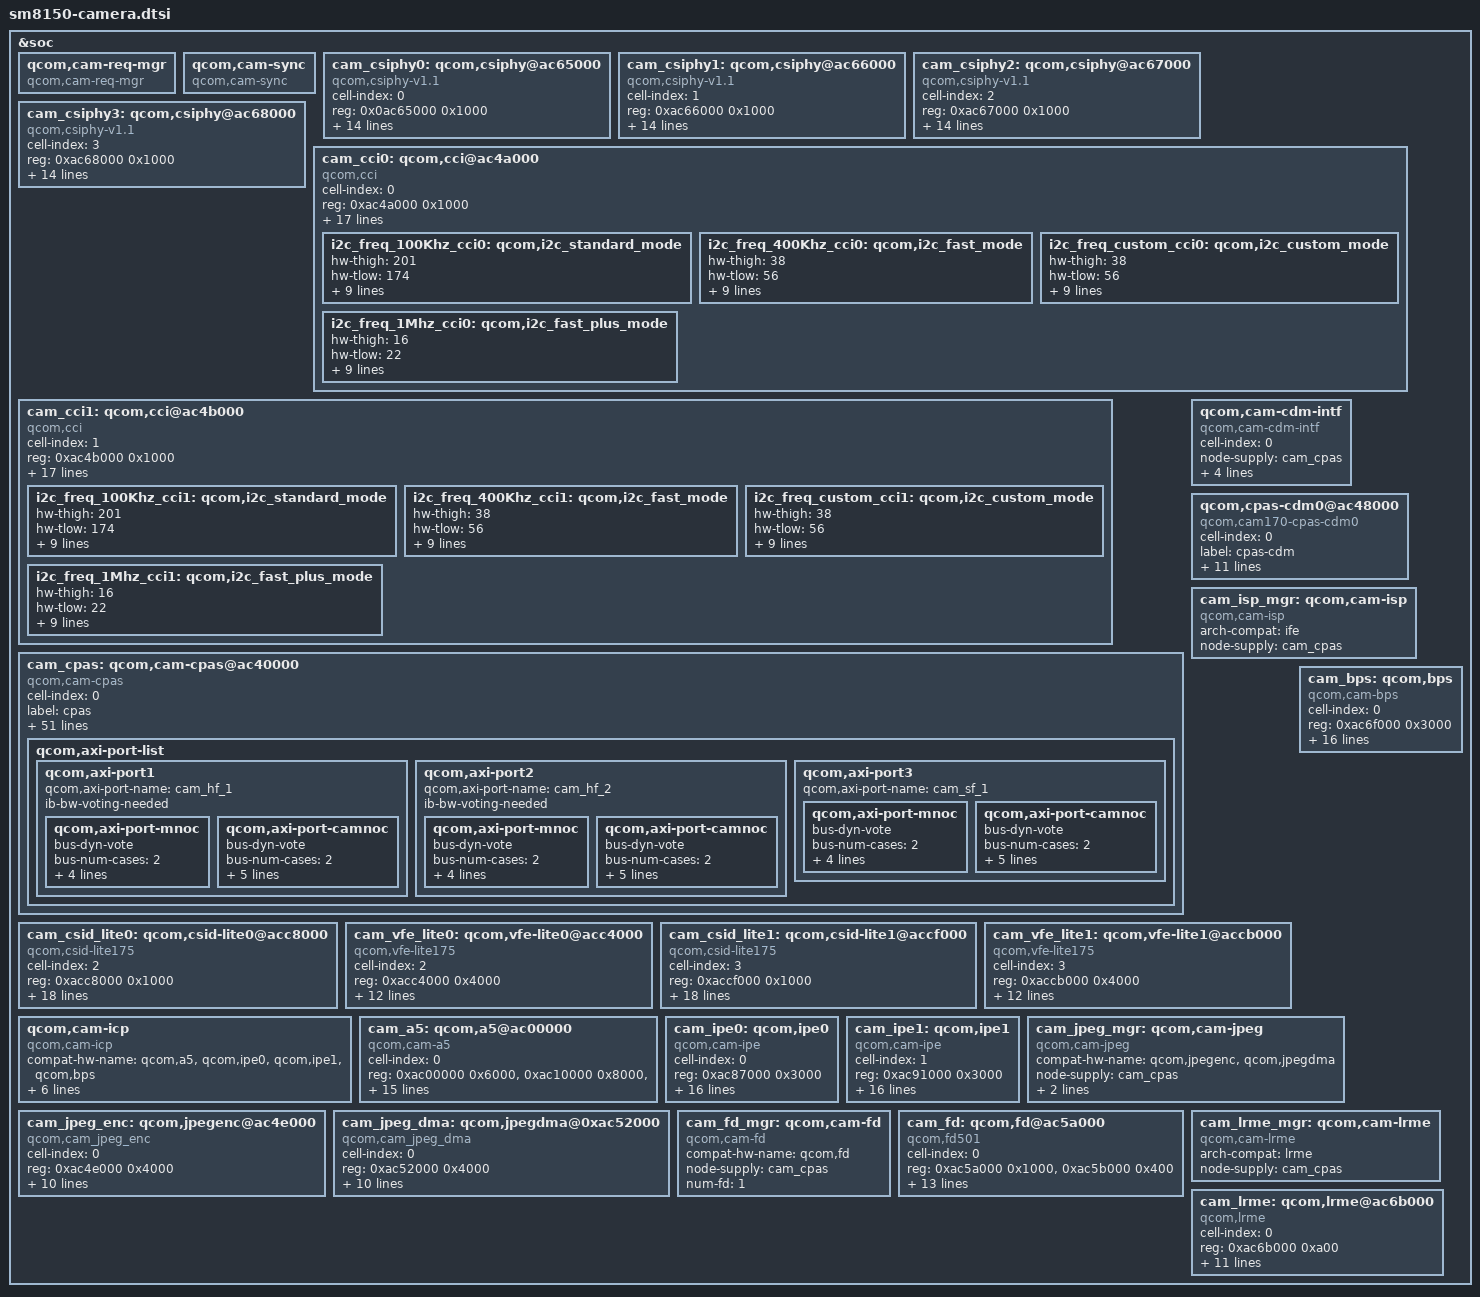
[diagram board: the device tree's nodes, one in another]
&soc {
	qcom,cam-req-mgr {
		compatible = "qcom,cam-req-mgr";
		status = "ok";
	};

	qcom,cam-sync {
		compatible = "qcom,cam-sync";
		status = "ok";
	};

	cam_csiphy0: qcom,csiphy@ac65000 {
		cell-index = <0>;
		compatible = "qcom,csiphy-v1.1", "qcom,csiphy";
		reg = <0x0ac65000 0x1000>;
		reg-names = "csiphy";
		reg-cam-base = <0x65000>;
		interrupts = <GIC_SPI 477 IRQ_TYPE_EDGE_RISING>;
		interrupt-names = "csiphy";
		gdscr-supply = <&titan_top_gdsc>;
		regulator-names = "gdscr";
		csi-vdd-voltage = <1200000>;
		mipi-csi-vdd-supply = <&pm8150l_l3>;
		clocks = <&camcc CAM_CC_CPHY_RX_CLK_SRC>,
			<&camcc CAM_CC_CSIPHY0_CLK>,
			<&camcc CAM_CC_CSI0PHYTIMER_CLK_SRC>,
			<&camcc CAM_CC_CSI0PHYTIMER_CLK>;
		clock-names = "cphy_rx_clk_src",
			"csiphy0_clk",
			"csi0phytimer_clk_src",
			"csi0phytimer_clk";
		src-clock-name = "csi0phytimer_clk_src";
		clock-cntl-level = "turbo";
		clock-rates =
			<400000000 0 300000000 0>;
		status = "ok";
		node-supply = <&cam_cpas>;
	};

	cam_csiphy1: qcom,csiphy@ac66000{
		cell-index = <1>;
		compatible = "qcom,csiphy-v1.1", "qcom,csiphy";
		reg = <0xac66000 0x1000>;
		reg-names = "csiphy";
		reg-cam-base = <0x66000>;
		interrupts = <GIC_SPI 478 IRQ_TYPE_EDGE_RISING>;
		interrupt-names = "csiphy";
		gdscr-supply = <&titan_top_gdsc>;
		regulator-names = "gdscr";
		csi-vdd-voltage = <1200000>;
		mipi-csi-vdd-supply = <&pm8150l_l3>;
		clocks = <&camcc CAM_CC_CPHY_RX_CLK_SRC>,
			<&camcc CAM_CC_CSIPHY1_CLK>,
			<&camcc CAM_CC_CSI1PHYTIMER_CLK_SRC>,
			<&camcc CAM_CC_CSI1PHYTIMER_CLK>;
		clock-names = "cphy_rx_clk_src",
			"csiphy1_clk",
			"csi1phytimer_clk_src",
			"csi1phytimer_clk";
		src-clock-name = "csi1phytimer_clk_src";
		clock-cntl-level = "turbo";
		clock-rates =
			<400000000 0 300000000 0>;

		status = "ok";
		node-supply = <&cam_cpas>;
	};

	cam_csiphy2: qcom,csiphy@ac67000 {
		cell-index = <2>;
		compatible = "qcom,csiphy-v1.1", "qcom,csiphy";
		reg = <0xac67000 0x1000>;
		reg-names = "csiphy";
		reg-cam-base = <0x67000>;
		interrupts = <GIC_SPI 479 IRQ_TYPE_EDGE_RISING>;
		interrupt-names = "csiphy";
		gdscr-supply = <&titan_top_gdsc>;
		regulator-names = "gdscr";
		csi-vdd-voltage = <1200000>;
		mipi-csi-vdd-supply = <&pm8150l_l3>;
		clocks = <&camcc CAM_CC_CPHY_RX_CLK_SRC>,
			<&camcc CAM_CC_CSIPHY2_CLK>,
			<&camcc CAM_CC_CSI2PHYTIMER_CLK_SRC>,
			<&camcc CAM_CC_CSI2PHYTIMER_CLK>;
		clock-names = "cphy_rx_clk_src",
			"csiphy2_clk",
			"csi2phytimer_clk_src",
			"csi2phytimer_clk";
		src-clock-name = "csi2phytimer_clk_src";
		clock-cntl-level = "turbo";
		clock-rates =
			<400000000 0 300000000 0>;
		status = "ok";
		node-supply = <&cam_cpas>;
	};

	cam_csiphy3: qcom,csiphy@ac68000 {
		cell-index = <3>;
		compatible = "qcom,csiphy-v1.1", "qcom,csiphy";
		reg = <0xac68000 0x1000>;
		reg-names = "csiphy";
		reg-cam-base = <0x68000>;
		interrupts = <GIC_SPI 448 IRQ_TYPE_EDGE_RISING>;
		interrupt-names = "csiphy";
		gdscr-supply = <&titan_top_gdsc>;
		regulator-names = "gdscr";
		csi-vdd-voltage = <1200000>;
		mipi-csi-vdd-supply = <&pm8150l_l3>;
		clocks = <&camcc CAM_CC_CPHY_RX_CLK_SRC>,
			<&camcc CAM_CC_CSIPHY3_CLK>,
			<&camcc CAM_CC_CSI3PHYTIMER_CLK_SRC>,
			<&camcc CAM_CC_CSI3PHYTIMER_CLK>;
		clock-names = "cphy_rx_clk_src",
			"csiphy3_clk",
			"csi3phytimer_clk_src",
			"csi3phytimer_clk";
		src-clock-name = "csi3phytimer_clk_src";
		clock-cntl-level = "turbo";
		clock-rates =
			<400000000 0 300000000 0>;
		status = "ok";
		node-supply = <&cam_cpas>;
	};

	cam_cci0: qcom,cci@ac4a000 {
		cell-index = <0>;
		compatible = "qcom,cci", "simple-bus";
		#address-cells = <1>;
		#size-cells = <0>;
		reg = <0xac4a000 0x1000>;
		reg-names = "cci";
		reg-cam-base = <0x4a000>;
		interrupt-names = "cci";
		interrupts = <GIC_SPI 460 IRQ_TYPE_EDGE_RISING>;
		status = "ok";
		gdscr-supply = <&titan_top_gdsc>;
		regulator-names = "gdscr";
		clocks = <&camcc CAM_CC_CCI_0_CLK_SRC>,
			<&camcc CAM_CC_CCI_0_CLK>;
		clock-names = "cci_0_clk_src",
			"cci_0_clk";
		src-clock-name = "cci_0_clk_src";
		clock-cntl-level = "lowsvs";
		clock-rates = <37500000 0>;
		pinctrl-names = "cam_default", "cam_suspend";
		pinctrl-0 = <&cci0_active &cci1_active>;
		pinctrl-1 = <&cci0_suspend &cci1_suspend>;
		node-supply = <&cam_cpas>;
		gpios = <&tlmm 17 0>,
			<&tlmm 18 0>,
			<&tlmm 19 0>,
			<&tlmm 20 0>;
		gpio-req-tbl-num = <0 1 2 3>;
		gpio-req-tbl-flags = <1 1 1 1>;
		gpio-req-tbl-label = "CCI_I2C_DATA0",
					"CCI_I2C_CLK0",
					"CCI_I2C_DATA1",
					"CCI_I2C_CLK1";

		i2c_freq_100Khz_cci0: qcom,i2c_standard_mode {
			hw-thigh = <201>;
			hw-tlow = <174>;
			hw-tsu-sto = <204>;
			hw-tsu-sta = <231>;
			hw-thd-dat = <22>;
			hw-thd-sta = <162>;
			hw-tbuf = <227>;
			hw-scl-stretch-en = <0>;
			hw-trdhld = <6>;
			hw-tsp = <3>;
			cci-clk-src = <37500000>;
			status = "ok";
		};

		i2c_freq_400Khz_cci0: qcom,i2c_fast_mode {
			hw-thigh = <38>;
			hw-tlow = <56>;
			hw-tsu-sto = <40>;
			hw-tsu-sta = <40>;
			hw-thd-dat = <22>;
			hw-thd-sta = <35>;
			hw-tbuf = <62>;
			hw-scl-stretch-en = <0>;
			hw-trdhld = <6>;
			hw-tsp = <3>;
			cci-clk-src = <37500000>;
			status = "ok";
		};

		i2c_freq_custom_cci0: qcom,i2c_custom_mode {
			hw-thigh = <38>;
			hw-tlow = <56>;
			hw-tsu-sto = <40>;
			hw-tsu-sta = <40>;
			hw-thd-dat = <22>;
			hw-thd-sta = <35>;
			hw-tbuf = <62>;
			hw-scl-stretch-en = <1>;
			hw-trdhld = <6>;
			hw-tsp = <3>;
			cci-clk-src = <37500000>;
			status = "ok";
		};

		i2c_freq_1Mhz_cci0: qcom,i2c_fast_plus_mode {
			hw-thigh = <16>;
			hw-tlow = <22>;
			hw-tsu-sto = <17>;
			hw-tsu-sta = <18>;
			hw-thd-dat = <16>;
			hw-thd-sta = <15>;
			hw-tbuf = <24>;
			hw-scl-stretch-en = <0>;
			hw-trdhld = <3>;
			hw-tsp = <3>;
			cci-clk-src = <37500000>;
			status = "ok";
		};
	};

	cam_cci1: qcom,cci@ac4b000 {
		cell-index = <1>;
		compatible = "qcom,cci", "simple-bus";
		#address-cells = <1>;
		#size-cells = <0>;
		reg = <0xac4b000 0x1000>;
		reg-names = "cci";
		reg-cam-base = <0x4b000>;
		interrupt-names = "cci";
		interrupts = <GIC_SPI 271 IRQ_TYPE_EDGE_RISING>;
		status = "ok";
		gdscr-supply = <&titan_top_gdsc>;
		regulator-names = "gdscr";
		clocks = <&camcc CAM_CC_CCI_1_CLK_SRC>,
			<&camcc CAM_CC_CCI_1_CLK>;
		clock-names = "cci_1_clk_src",
			"cci_1_clk";
		src-clock-name = "cci_1_clk_src";
		clock-cntl-level = "lowsvs";
		clock-rates = <37500000 0>;
		pinctrl-names = "cam_default", "cam_suspend";
		pinctrl-0 = <&cci2_active &cci3_active>;
		pinctrl-1 = <&cci2_suspend &cci3_suspend>;
		node-supply = <&cam_cpas>;
		gpios = <&tlmm 31 0>,
			<&tlmm 32 0>,
			<&tlmm 33 0>,
			<&tlmm 34 0>;
		gpio-req-tbl-num = <0 1 2 3>;
		gpio-req-tbl-flags = <1 1 1 1>;
		gpio-req-tbl-label = "CCI_I2C_DATA2",
					"CCI_I2C_CLK2",
					"CCI_I2C_DATA3",
					"CCI_I2C_CLK3";

		i2c_freq_100Khz_cci1: qcom,i2c_standard_mode {
			hw-thigh = <201>;
			hw-tlow = <174>;
			hw-tsu-sto = <204>;
			hw-tsu-sta = <231>;
			hw-thd-dat = <22>;
			hw-thd-sta = <162>;
			hw-tbuf = <227>;
			hw-scl-stretch-en = <0>;
			hw-trdhld = <6>;
			hw-tsp = <3>;
			cci-clk-src = <37500000>;
			status = "ok";
		};

		i2c_freq_400Khz_cci1: qcom,i2c_fast_mode {
			hw-thigh = <38>;
			hw-tlow = <56>;
			hw-tsu-sto = <40>;
			hw-tsu-sta = <40>;
			hw-thd-dat = <22>;
			hw-thd-sta = <35>;
			hw-tbuf = <62>;
			hw-scl-stretch-en = <0>;
			hw-trdhld = <6>;
			hw-tsp = <3>;
			cci-clk-src = <37500000>;
			status = "ok";
		};

		i2c_freq_custom_cci1: qcom,i2c_custom_mode {
			hw-thigh = <38>;
			hw-tlow = <56>;
			hw-tsu-sto = <40>;
			hw-tsu-sta = <40>;
			hw-thd-dat = <22>;
			hw-thd-sta = <35>;
			hw-tbuf = <62>;
			hw-scl-stretch-en = <1>;
			hw-trdhld = <6>;
			hw-tsp = <3>;
			cci-clk-src = <37500000>;
			status = "ok";
		};

		i2c_freq_1Mhz_cci1: qcom,i2c_fast_plus_mode {
			hw-thigh = <16>;
			hw-tlow = <22>;
			hw-tsu-sto = <17>;
			hw-tsu-sta = <18>;
			hw-thd-dat = <16>;
			hw-thd-sta = <15>;
			hw-tbuf = <24>;
			hw-scl-stretch-en = <0>;
			hw-trdhld = <3>;
			hw-tsp = <3>;
			cci-clk-src = <37500000>;
			status = "ok";
		};
	};

	cam_cpas: qcom,cam-cpas@ac40000 {
		cell-index = <0>;
		compatible = "qcom,cam-cpas";
		label = "cpas";
		arch-compat = "cpas_top";
		status = "ok";
		reg-names = "cam_cpas_top", "cam_camnoc";
		reg = <0xac40000 0x1000>,
			<0xac42000 0x5000>;
		reg-cam-base = <0x40000 0x42000>;
		interrupt-names = "cpas_camnoc";
		interrupts = <GIC_SPI 459 IRQ_TYPE_EDGE_RISING>;
		camnoc-axi-min-ib-bw = <3000000000>;
		regulator-names = "camss-vdd";
		camss-vdd-supply = <&titan_top_gdsc>;
		clock-names =
			"gcc_axi_hf_clk",
			"gcc_axi_sf_clk",
			"slow_ahb_clk_src",
			"cpas_ahb_clk",
			"camnoc_axi_clk_src",
			"camnoc_axi_clk";
		clocks =
			<&gcc GCC_CAMERA_HF_AXI_CLK>,
			<&gcc GCC_CAMERA_SF_AXI_CLK>,
			<&camcc CAM_CC_SLOW_AHB_CLK_SRC>,
			<&camcc CAM_CC_CPAS_AHB_CLK>,
			<&camcc CAM_CC_CAMNOC_AXI_CLK_SRC>,
			<&camcc CAM_CC_CAMNOC_AXI_CLK>;
		src-clock-name = "camnoc_axi_clk_src";
		clock-rates =
			<0 0 0 0 0 0>,
			<0 0 19200000 0 19200000 0>,
			<0 0 80000000 0 150000000 0>,
			<0 0 80000000 0 266670000 0>,
			<0 0 80000000 0 320000000 0>,
			<0 0 80000000 0 400000000 0>,
			<0 0 80000000 0 480000000 0>;
		clock-cntl-level = "suspend", "minsvs", "lowsvs", "svs",
			"svs_l1", "nominal", "turbo";
		control-camnoc-axi-clk;
		camnoc-bus-width = <32>;
		camnoc-axi-clk-bw-margin-perc = <20>;
		interconnect-names = "cam_ahb";
		interconnects =<&gem_noc MASTER_APPSS_PROC
			&config_noc SLAVE_CAMERA_CFG>;
		bus-num-cases = <7>;
		bus-num-paths = <1>;
		bus-bw-KBps =
			<0 0>, <0 76800>, <0 76800>, <0 150000>, <0 150000>,
			<0 300000>, <0 300000>;
		vdd-corners = <RPMH_REGULATOR_LEVEL_RETENTION
			RPMH_REGULATOR_LEVEL_MIN_SVS
			RPMH_REGULATOR_LEVEL_LOW_SVS
			RPMH_REGULATOR_LEVEL_SVS
			RPMH_REGULATOR_LEVEL_SVS_L1
			RPMH_REGULATOR_LEVEL_NOM
			RPMH_REGULATOR_LEVEL_NOM_L1
			RPMH_REGULATOR_LEVEL_NOM_L2
			RPMH_REGULATOR_LEVEL_TURBO
			RPMH_REGULATOR_LEVEL_TURBO_L1>;
		vdd-corner-ahb-mapping = "suspend",
			"minsvs", "lowsvs", "svs", "svs_l1",
			"nominal", "nominal", "nominal",
			"turbo", "turbo";
		client-id-based;
		client-names =
			"csiphy0", "csiphy1", "csiphy2", "csiphy3",
			"cci0", "cci1",
			"csid0", "csid1", "csid2", "csid3",
			"ife0", "ife1", "ife2", "ife3",
			"ipe0", "ipe1", "cam-cdm-intf0", "cpas-cdm0",
			"bps0", "icp0", "jpeg-dma0", "jpeg-enc0",
			"fd0", "lrmecpas0";
		client-axi-port-names =
			"cam_hf_1", "cam_hf_2", "cam_hf_1", "cam_hf_2",
			"cam_sf_1", "cam_sf_1",
			"cam_hf_1", "cam_hf_2", "cam_hf_1", "cam_hf_2",
			"cam_hf_1", "cam_hf_2", "cam_hf_1", "cam_hf_2",
			"cam_sf_1", "cam_sf_1", "cam_sf_1", "cam_sf_1",
			"cam_sf_1", "cam_sf_1", "cam_sf_1", "cam_sf_1",
			"cam_sf_1", "cam_sf_1";
		client-bus-camnoc-based;
		qcom,axi-port-list {
			qcom,axi-port1 {
				qcom,axi-port-name = "cam_hf_1";
				ib-bw-voting-needed;
				qcom,axi-port-mnoc {
					interconnect-names = "cam_hf_1_mnoc";
					bus-dyn-vote;
					bus-num-cases = <2>;
					bus-num-paths = <1>;
					interconnects = <&mmss_noc MASTER_CAMNOC_HF0
						&mc_virt SLAVE_EBI1>;
					bus-bw-KBps =
						<0 0>, <0 0>;
				};
				qcom,axi-port-camnoc {
					interconnect-names = "cam_hf_1_camnoc";
					bus-dyn-vote;
					bus-num-cases = <2>;
					bus-num-paths = <1>;
					interconnects = <&camnoc_virt MASTER_CAMNOC_HF0_UNCOMP
						&camnoc_virt SLAVE_CAMNOC_UNCOMP>;
					bus-bw-KBps =
						<0 0>, <0 0>;
				};
			};
			qcom,axi-port2 {
				qcom,axi-port-name = "cam_hf_2";
				ib-bw-voting-needed;
				qcom,axi-port-mnoc {
					interconnect-names = "cam_hf_2_mnoc";
					bus-dyn-vote;
					bus-num-cases = <2>;
					bus-num-paths = <1>;
					interconnects = <&mmss_noc MASTER_CAMNOC_HF1
						&mc_virt SLAVE_EBI1>;
					bus-bw-KBps =
						<0 0>, <0 0>;
				};
				qcom,axi-port-camnoc {
					interconnect-names = "cam_hf_2_camnoc";
					bus-dyn-vote;
					bus-num-cases = <2>;
					bus-num-paths = <1>;
					interconnects = <&camnoc_virt MASTER_CAMNOC_HF1_UNCOMP
						&camnoc_virt SLAVE_CAMNOC_UNCOMP>;
					bus-bw-KBps =
						<0 0>, <0 0>;
				};
			};
			qcom,axi-port3 {
				qcom,axi-port-name = "cam_sf_1";
				qcom,axi-port-mnoc {
					interconnect-names = "cam_sf_1_mnoc";
					bus-dyn-vote;
					bus-num-cases = <2>;
					bus-num-paths = <1>;
					interconnects = <&mmss_noc MASTER_CAMNOC_SF
						&mc_virt SLAVE_EBI1>;
					bus-bw-KBps =
						<0 0>, <0 0>;
				};
				qcom,axi-port-camnoc {
					interconnect-names = "cam_sf_1_camnoc";
					bus-dyn-vote;
					bus-num-cases = <2>;
					bus-num-paths = <1>;
					interconnects = <&camnoc_virt MASTER_CAMNOC_SF_UNCOMP
						&camnoc_virt SLAVE_CAMNOC_UNCOMP>;
					bus-bw-KBps =
						<0 0>, <0 0>;
				};
			};
		};
	};

	qcom,cam-cdm-intf {
		compatible = "qcom,cam-cdm-intf";
		cell-index = <0>;
		node-supply = <&cam_cpas>;
		label = "cam-cdm-intf";
		num-hw-cdm = <1>;
		cdm-client-names = "vfe",
			"jpegdma",
			"jpegenc",
			"fd",
			"lrmecdm";
		status = "ok";
	};

	qcom,cpas-cdm0@ac48000 {
		cell-index = <0>;
		compatible = "qcom,cam170-cpas-cdm0";
		label = "cpas-cdm";
		reg = <0xac48000 0x1000>;
		reg-names = "cpas-cdm";
		reg-cam-base = <0x48000>;
		interrupts = <GIC_SPI 461 IRQ_TYPE_EDGE_RISING>;
		interrupt-names = "cpas-cdm";
		regulator-names = "camss";
		camss-supply = <&titan_top_gdsc>;
		node-supply = <&cam_cpas>;
		clock-names = "cam_cc_cpas_slow_ahb_clk",
			"cam_cc_cpas_ahb_clk";
		clocks = <&camcc CAM_CC_SLOW_AHB_CLK_SRC>,
			<&camcc CAM_CC_CPAS_AHB_CLK>;
		clock-rates = <0 0>;
		clock-cntl-level = "svs";
		cdm-client-names = "ife";
		status = "ok";
	};

	cam_isp_mgr: qcom,cam-isp {
		compatible = "qcom,cam-isp";
		arch-compat = "ife";
		status = "ok";
		node-supply = <&cam_cpas>;
	};

	cam_csid_lite0: qcom,csid-lite0@acc8000 {
		cell-index = <2>;
		compatible = "qcom,csid-lite175";
		reg-names = "csid-lite";
		reg = <0xacc8000 0x1000>;
		reg-cam-base = <0xc8000>;
		interrupt-names = "csid-lite";
		interrupts = <GIC_SPI 468 IRQ_TYPE_EDGE_RISING>;
		regulator-names = "camss";
		camss-supply = <&titan_top_gdsc>;
		clock-names =
			"ife_csid_clk_src",
			"ife_csid_clk",
			"cphy_rx_clk_src",
			"ife_cphy_rx_clk",
			"ife_clk_src",
			"ife_clk";
		clocks =
			<&camcc CAM_CC_IFE_LITE_0_CSID_CLK_SRC>,
			<&camcc CAM_CC_IFE_LITE_0_CSID_CLK>,
			<&camcc CAM_CC_CPHY_RX_CLK_SRC>,
			<&camcc CAM_CC_IFE_LITE_0_CPHY_RX_CLK>,
			<&camcc CAM_CC_IFE_LITE_0_CLK_SRC>,
			<&camcc CAM_CC_IFE_LITE_0_CLK>;
		clock-rates =
			<400000000 0 0 0 320000000 0>,
			<400000000 0 0 0 400000000 0>,
			<480000000 0 0 0 480000000 0>,
			<600000000 0 0 0 600000000 0>;
		clock-cntl-level = "lowsvs", "svs", "svs_l1", "turbo";
		src-clock-name = "ife_csid_clk_src";
		clock-control-debugfs = "true";
		status = "ok";
		node-supply = <&cam_cpas>;
	};

	cam_vfe_lite0: qcom,vfe-lite0@acc4000 {
		cell-index = <2>;
		compatible = "qcom,vfe-lite175";
		reg-names = "ife-lite";
		reg = <0xacc4000 0x4000>;
		reg-cam-base = <0xc4000>;
		interrupt-names = "ife-lite";
		interrupts = <GIC_SPI 469 IRQ_TYPE_EDGE_RISING>;
		regulator-names = "camss";
		camss-supply = <&titan_top_gdsc>;
		clock-names =
			"ife_clk_src",
			"ife_clk";
		clocks =
			<&camcc CAM_CC_IFE_LITE_0_CLK_SRC>,
			<&camcc CAM_CC_IFE_LITE_0_CLK>;
		clock-rates =
			<320000000 0>,
			<400000000 0>,
			<480000000 0>,
			<600000000 0>;
		clock-cntl-level = "lowsvs", "svs", "svs_l1", "turbo";
		src-clock-name = "ife_clk_src";
		clock-control-debugfs = "true";
		status = "ok";
		node-supply = <&cam_cpas>;
	};

	cam_csid_lite1: qcom,csid-lite1@accf000 {
		cell-index = <3>;
		compatible = "qcom,csid-lite175";
		reg-names = "csid-lite";
		reg = <0xaccf000 0x1000>;
		reg-cam-base = <0xcf000>;
		interrupt-names = "csid-lite";
		interrupts = <GIC_SPI 359 IRQ_TYPE_EDGE_RISING>;
		regulator-names = "camss";
		camss-supply = <&titan_top_gdsc>;
		clock-names =
			"ife_csid_clk_src",
			"ife_csid_clk",
			"cphy_rx_clk_src",
			"ife_cphy_rx_clk",
			"ife_clk_src",
			"ife_clk";
		clocks =
			<&camcc CAM_CC_IFE_LITE_1_CSID_CLK_SRC>,
			<&camcc CAM_CC_IFE_LITE_1_CSID_CLK>,
			<&camcc CAM_CC_CPHY_RX_CLK_SRC>,
			<&camcc CAM_CC_IFE_LITE_1_CPHY_RX_CLK>,
			<&camcc CAM_CC_IFE_LITE_1_CLK_SRC>,
			<&camcc CAM_CC_IFE_LITE_1_CLK>;
		clock-rates =
			<400000000 0 0 0 320000000 0>,
			<400000000 0 0 0 400000000 0>,
			<480000000 0 0 0 480000000 0>,
			<600000000 0 0 0 600000000 0>;
		clock-cntl-level = "lowsvs", "svs", "svs_l1", "turbo";
		src-clock-name = "ife_csid_clk_src";
		clock-control-debugfs = "true";
		status = "ok";
		node-supply = <&cam_cpas>;
	};

	cam_vfe_lite1: qcom,vfe-lite1@accb000 {
		cell-index = <3>;
		compatible = "qcom,vfe-lite175";
		reg-names = "ife-lite";
		reg = <0xaccb000 0x4000>;
		reg-cam-base = <0xcb000>;
		interrupt-names = "ife-lite";
		interrupts = <GIC_SPI 360 IRQ_TYPE_EDGE_RISING>;
		regulator-names = "camss";
		camss-supply = <&titan_top_gdsc>;
		clock-names =
			"ife_clk_src",
			"ife_clk";
		clocks =
			<&camcc CAM_CC_IFE_LITE_1_CLK_SRC>,
			<&camcc CAM_CC_IFE_LITE_1_CLK>;
		clock-rates =
			<320000000 0>,
			<400000000 0>,
			<480000000 0>,
			<600000000 0>;
		clock-cntl-level = "lowsvs", "svs", "svs_l1", "turbo";
		src-clock-name = "ife_clk_src";
		clock-control-debugfs = "true";
		status = "ok";
		node-supply = <&cam_cpas>;
	};

	qcom,cam-icp {
		compatible = "qcom,cam-icp";
		compat-hw-name = "qcom,a5",
			"qcom,ipe0",
			"qcom,ipe1",
			"qcom,bps";
		num-a5 = <1>;
		num-ipe = <2>;
		num-bps = <1>;
		icp_pc_en;
		ipe_bps_pc_en;
		status = "ok";
		node-supply = <&cam_cpas>;
	};

	cam_a5: qcom,a5@ac00000 {
		cell-index = <0>;
		compatible = "qcom,cam-a5";
		reg = <0xac00000 0x6000>,
			<0xac10000 0x8000>,
			<0xac18000 0x3000>;
		reg-names = "a5_qgic", "a5_sierra", "a5_csr";
		reg-cam-base = <0x00000 0x10000 0x18000>;
		interrupts = <GIC_SPI 463 IRQ_TYPE_EDGE_RISING>;
		interrupt-names = "a5";
		regulator-names = "camss-vdd";
		camss-vdd-supply = <&titan_top_gdsc>;
		clock-names =
			"soc_fast_ahb",
			"icp_ahb_clk",
			"icp_clk_src",
			"icp_clk";
		clocks =
			<&camcc CAM_CC_FAST_AHB_CLK_SRC>,
			<&camcc CAM_CC_ICP_AHB_CLK>,
			<&camcc CAM_CC_ICP_CLK_SRC>,
			<&camcc CAM_CC_ICP_CLK>;
		clock-rates =
			<200000000 0 400000000 0>,
			<400000000 0 600000000 0>;
		clock-cntl-level = "svs", "turbo";
		fw_name = "CAMERA_ICP.elf";
		ubwc-cfg = <0x7B 0x1EF>;
		status = "ok";
		node-supply = <&cam_cpas>;
	};

	cam_ipe0: qcom,ipe0 {
		cell-index = <0>;
		compatible = "qcom,cam-ipe";
		reg = <0xac87000 0x3000>;
		reg-names = "ipe0_top";
		reg-cam-base = <0x87000>;
		regulator-names = "ipe0-vdd";
		ipe0-vdd-supply = <&ipe_0_gdsc>;
		clock-names =
			"ipe_0_ahb_clk",
			"ipe_0_areg_clk",
			"ipe_0_axi_clk",
			"ipe_0_clk_src",
			"ipe_0_clk";
		src-clock-name = "ipe_0_clk_src";
		clock-control-debugfs = "true";
		clocks =
			<&camcc CAM_CC_IPE_0_AHB_CLK>,
			<&camcc CAM_CC_IPE_0_AREG_CLK>,
			<&camcc CAM_CC_IPE_0_AXI_CLK>,
			<&camcc CAM_CC_IPE_0_CLK_SRC>,
			<&camcc CAM_CC_IPE_0_CLK>;
		clock-rates =
			<0 0 0 300000000 0>,
			<0 0 0 475000000 0>,
			<0 0 0 520000000 0>,
			<0 0 0 600000000 0>,
			<0 0 0 600000000 0>;
		clock-cntl-level = "lowsvs", "svs", "svs_l1",
				"nominal", "turbo";
		status = "ok";
		node-supply = <&cam_cpas>;
	};

	cam_ipe1: qcom,ipe1 {
		cell-index = <1>;
		compatible = "qcom,cam-ipe";
		reg = <0xac91000 0x3000>;
		reg-names = "ipe1_top";
		reg-cam-base = <0x91000>;
		regulator-names = "ipe1-vdd";
		ipe1-vdd-supply = <&ipe_1_gdsc>;
		clock-names =
			"ipe_1_ahb_clk",
			"ipe_1_areg_clk",
			"ipe_1_axi_clk",
			"ipe_1_clk_src",
			"ipe_1_clk";
		src-clock-name = "ipe_1_clk_src";
		clock-control-debugfs = "true";
		clocks =
			<&camcc CAM_CC_IPE_1_AHB_CLK>,
			<&camcc CAM_CC_IPE_1_AREG_CLK>,
			<&camcc CAM_CC_IPE_1_AXI_CLK>,
			<&camcc CAM_CC_IPE_0_CLK_SRC>,
			<&camcc CAM_CC_IPE_1_CLK>;
		clock-rates =
			<0 0 0 300000000 0>,
			<0 0 0 475000000 0>,
			<0 0 0 520000000 0>,
			<0 0 0 600000000 0>,
			<0 0 0 600000000 0>;
		clock-cntl-level = "lowsvs", "svs", "svs_l1",
				"nominal", "turbo";
		status = "ok";
		node-supply = <&cam_cpas>;
	};

	cam_bps: qcom,bps {
		cell-index = <0>;
		compatible = "qcom,cam-bps";
		reg = <0xac6f000 0x3000>;
		reg-names = "bps_top";
		reg-cam-base = <0x6f000>;
		regulator-names = "bps-vdd";
		bps-vdd-supply = <&bps_gdsc>;
		clock-names =
			"bps_ahb_clk",
			"bps_areg_clk",
			"bps_axi_clk",
			"bps_clk_src",
			"bps_clk";
		src-clock-name = "bps_clk_src";
		clock-control-debugfs = "true";
		clocks =
			<&camcc CAM_CC_BPS_AHB_CLK>,
			<&camcc CAM_CC_BPS_AREG_CLK>,
			<&camcc CAM_CC_BPS_AXI_CLK>,
			<&camcc CAM_CC_BPS_CLK_SRC>,
			<&camcc CAM_CC_BPS_CLK>;
		clock-rates =
			<0 0 0 200000000 0>,
			<0 0 0 400000000 0>,
			<0 0 0 480000000 0>,
			<0 0 0 600000000 0>,
			<0 0 0 600000000 0>;
		clock-cntl-level = "lowsvs", "svs", "svs_l1",
				"nominal", "turbo";
		status = "ok";
		node-supply = <&cam_cpas>;
	};

	cam_jpeg_mgr: qcom,cam-jpeg {
		compatible = "qcom,cam-jpeg";
		compat-hw-name = "qcom,jpegenc",
			"qcom,jpegdma";
		node-supply = <&cam_cpas>;
		num-jpeg-enc = <1>;
		num-jpeg-dma = <1>;
		status = "ok";
	};

	cam_jpeg_enc: qcom,jpegenc@ac4e000 {
		cell-index = <0>;
		compatible = "qcom,cam_jpeg_enc";
		reg-names = "jpege_hw";
		reg = <0xac4e000 0x4000>;
		reg-cam-base = <0x4e000>;
		interrupt-names = "jpeg";
		interrupts = <GIC_SPI 474 IRQ_TYPE_EDGE_RISING>;
		regulator-names = "camss-vdd";
		camss-vdd-supply = <&titan_top_gdsc>;
		node-supply = <&cam_cpas>;
		clock-names =
			"jpegenc_clk_src",
			"jpegenc_clk";
		clocks =
			<&camcc CAM_CC_JPEG_CLK_SRC>,
			<&camcc CAM_CC_JPEG_CLK>;

		clock-rates = <600000000 0>;
		src-clock-name = "jpegenc_clk_src";
		clock-cntl-level = "nominal";
		status = "ok";
	};

	cam_jpeg_dma: qcom,jpegdma@0xac52000{
		cell-index = <0>;
		compatible = "qcom,cam_jpeg_dma";
		reg-names = "jpegdma_hw";
		reg = <0xac52000 0x4000>;
		reg-cam-base = <0x52000>;
		interrupt-names = "jpegdma";
		interrupts = <GIC_SPI 475 IRQ_TYPE_EDGE_RISING>;
		regulator-names = "camss-vdd";
		camss-vdd-supply = <&titan_top_gdsc>;
		node-supply = <&cam_cpas>;
		clock-names =
			"jpegdma_clk_src",
			"jpegdma_clk";
		clocks =
			<&camcc CAM_CC_JPEG_CLK_SRC>,
			<&camcc CAM_CC_JPEG_CLK>;

		clock-rates = <600000000 0>;
		src-clock-name = "jpegdma_clk_src";
		clock-cntl-level = "nominal";
		status = "ok";
	};
	cam_fd_mgr: qcom,cam-fd {
		compatible = "qcom,cam-fd";
		compat-hw-name = "qcom,fd";
		node-supply = <&cam_cpas>;
		num-fd = <1>;
		status = "ok";
	};

	cam_fd: qcom,fd@ac5a000 {
		cell-index = <0>;
		compatible = "qcom,fd501";
		reg-names = "fd_core", "fd_wrapper";
		reg = <0xac5a000 0x1000>,
			<0xac5b000 0x400>;
		reg-cam-base = <0x5a000 0x5b000>;
		interrupt-names = "fd";
		interrupts = <0 462 0>;
		regulator-names = "camss-vdd";
		camss-vdd-supply = <&titan_top_gdsc>;
		node-supply = <&cam_cpas>;
		clock-names =
			"fd_core_clk_src",
			"fd_core_clk",
			"fd_core_uar_clk";
		clocks =
			<&camcc CAM_CC_FD_CORE_CLK_SRC>,
			<&camcc CAM_CC_FD_CORE_CLK>,
			<&camcc CAM_CC_FD_CORE_UAR_CLK>;
		src-clock-name = "fd_core_clk_src";
		clock-control-debugfs = "true";
		clock-cntl-level = "svs", "svs_l1", "turbo";
		clock-rates =
			<400000000 0 0>,
			<480000000 0 0>,
			<600000000 0 0>;
		status = "ok";
	};

	cam_lrme_mgr: qcom,cam-lrme {
		compatible = "qcom,cam-lrme";
		arch-compat = "lrme";
		node-supply = <&cam_cpas>;
		status = "ok";
	};

	cam_lrme: qcom,lrme@ac6b000 {
		cell-index = <0>;
		compatible = "qcom,lrme";
		reg-names = "lrme";
		reg = <0xac6b000 0xa00>;
		reg-cam-base = <0x6b000>;
		interrupt-names = "lrme";
		interrupts = <0 476 0>;
		regulator-names = "camss";
		camss-supply = <&titan_top_gdsc>;
		node-supply = <&cam_cpas>;
		clock-names =
			"lrme_clk_src",
			"lrme_clk";
		clocks =
			<&camcc CAM_CC_LRME_CLK_SRC>,
			<&camcc CAM_CC_LRME_CLK>;
		clock-rates =
			<240000000 0>,
			<300000000 0>,
			<320000000 0>,
			<400000000 0>;
		clock-cntl-level = "lowsvs", "svs", "svs_l1", "turbo";
		src-clock-name = "lrme_clk_src";
		status = "ok";
	};
};
